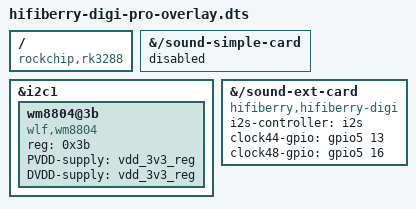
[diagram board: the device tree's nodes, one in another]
/dts-v1/;
/plugin/;

/ {
	compatible = "rockchip,rk3288";

	fragment@0 {
		target-path ="/sound-simple-card";
		__overlay__ {
			status = "disabled";
		};
	};

	fragment@1 {
		target = <&i2c1>;
		__overlay__ {
			#address-cells = <1>;
			#size-cells = <0>;
			status = "okay";

			wm8804@3b {
				#sound-dai-cells = <0>;
				compatible = "wlf,wm8804";
				reg = <0x3b>;
				PVDD-supply = <&vdd_3v3_reg>;
				DVDD-supply = <&vdd_3v3_reg>;
				status = "okay";
			};
		};
	};

	fragment@2 {
		target-path = "/sound-ext-card";
		__overlay__ {
			compatible = "hifiberry,hifiberry-digi";
			i2s-controller = <&i2s>;
			status = "okay";
			clock44-gpio = <&gpio5 13 0>;
			clock48-gpio = <&gpio5 16 0>;
		};
	};
};
